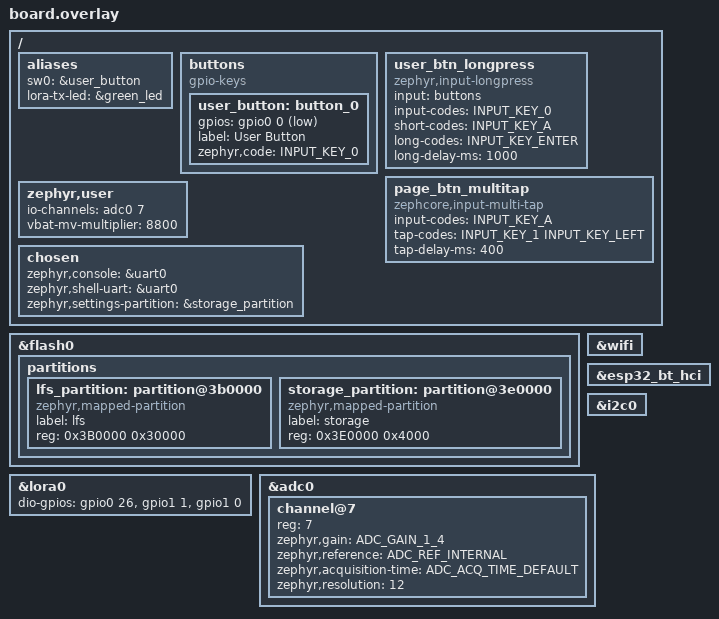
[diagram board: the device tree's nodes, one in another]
/*
 * SPDX-License-Identifier: MIT
 * TTGO LoRa32 — ZephCore overlay
 *
 * The upstream Zephyr DTS (ttgo_lora32_esp32_procpu.dts) already defines:
 *   SX1276 on SPI3 (NSS=GPIO18, SCK/MOSI/MISO via pinctrl)
 *   SSD1306 OLED on I2C0 (SDA=GPIO21, SCL=GPIO22)
 *   UART0 console (TX=GPIO1, RX=GPIO3)
 *   LED0 on GPIO25, WiFi
 *
 * LoRa SPI3 pins: NSS=18, DIO0=26, DIO1=33, DIO2=32
 * LoRa control:   RESET=23
 * Display I2C0:   SDA=21, SCL=22 (SSD1306 @ 0x3C)
 *
 * Flash layout (partitions_0x1000_amp_4M.dtsi):
 *   storage_partition @ 0x3B0000 (192KB) — repurposed as LittleFS
 */

#include <zephyr/dt-bindings/adc/adc.h>
#include <zephyr/dt-bindings/input/input-event-codes.h>

/ {
	aliases {
		sw0 = &user_button;
		lora-tx-led = &green_led;
	};

	buttons: buttons {
		compatible = "gpio-keys";
		user_button: button_0 {
			gpios = <&gpio0 0 (GPIO_PULL_UP | GPIO_ACTIVE_LOW)>;
			label = "User Button";
			zephyr,code = <INPUT_KEY_0>;
		};
	};

	user_btn_longpress {
		compatible = "zephyr,input-longpress";
		input = <&buttons>;
		input-codes = <INPUT_KEY_0>;
		short-codes = <INPUT_KEY_A>;
		long-codes = <INPUT_KEY_ENTER>;
		long-delay-ms = <1000>;
	};

	page_btn_multitap {
		compatible = "zephcore,input-multi-tap";
		input-codes = <INPUT_KEY_A>;
		tap-codes = <INPUT_KEY_1 INPUT_KEY_LEFT>;
		tap-delay-ms = <400>;
	};

	zephyr,user {
		io-channels = <&adc0 7>;
		vbat-mv-multiplier = <8800>;
	};

	chosen {
		/* UART0 console is correct for classic ESP32 (no native USB) */
		zephyr,console = &uart0;
		zephyr,shell-uart = &uart0;
	};
};

/*
 * Flash partitions — repurpose storage_partition as LittleFS.
 * The 4MB layout has appcpu slots we don't use (procpu-only build),
 * but we leave them to avoid changing the partition map.
 */
/delete-node/ &storage_partition;

/ {
	chosen {
		zephyr,settings-partition = &storage_partition;
	};
};

&flash0 {
	partitions {
		/* LittleFS 192KB for DataStore (identity, prefs, creds) */
		lfs_partition: partition@3b0000 {
			compatible = "zephyr,mapped-partition";
			label = "lfs";
			reg = <0x3B0000 0x30000>;
		};
		/* BLE bond store — 16KB NVS, isolated from /lfs (see esp32_common.conf).
		 * Placed in the unused scratch region just above lfs (lfs unchanged). */
		storage_partition: partition@3e0000 {
			compatible = "zephyr,mapped-partition";
			label = "storage";
			reg = <0x3E0000 0x4000>;
		};
	};
};

/* LittleFS auto-mount — standard /lfs mount point */
#include "../../common/filesystem.dtsi"

/* WiFi — required for observer MQTT connectivity */
&wifi {
	status = "okay";
};

/*
 * BT HCI controller — the upstream ttgo_lora32 DTS leaves the node disabled
 * (esp32_common.dtsi already sets chosen zephyr,bt-hci to it).  Companion
 * builds set CONFIG_BT=y, and the hal_espressif CMake compiles the ESP32 BT
 * controller under CONFIG_BT alone; without this node BT_ESP32 stays off and
 * its Kconfig symbols (CONFIG_ESP32_BT_CONTROLLER_TASK_PRIO etc.) are
 * undefined, breaking the bt.c compile.  Same fix as ttgo_tbeam.
 */
&esp32_bt_hci {
	status = "okay";
};

/* I2C sensors — auto-detected at runtime */
&i2c0 {
	#include "../../common/sensors-i2c.dtsi"
};

/* V2.1-1.6 radio interrupts; GPIO35 is the battery ADC input. */
&lora0 {
	dio-gpios = <&gpio0 26 (GPIO_PULL_DOWN | GPIO_ACTIVE_HIGH)>,
		    <&gpio1 1 (GPIO_PULL_DOWN | GPIO_ACTIVE_HIGH)>,
		    <&gpio1 0 (GPIO_PULL_DOWN | GPIO_ACTIVE_HIGH)>;
};

/* GPIO35 = ADC1 channel 7, with a 2:1 battery divider. */
&adc0 {
	status = "okay";
	#address-cells = <1>;
	#size-cells = <0>;

	channel@7 {
		reg = <7>;
		zephyr,gain = "ADC_GAIN_1_4";
		zephyr,reference = "ADC_REF_INTERNAL";
		zephyr,acquisition-time = <ADC_ACQ_TIME_DEFAULT>;
		zephyr,resolution = <12>;
	};
};
